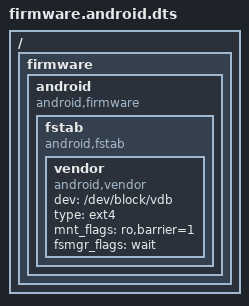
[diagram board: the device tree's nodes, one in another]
/ {
    firmware {
        android {
            compatible = "android,firmware";
            fstab {
                compatible = "android,fstab";
                vendor {
                    compatible = "android,vendor";
                    dev = "/dev/block/vdb";
                    type = "ext4";
                    mnt_flags = "ro,barrier=1";
                    fsmgr_flags = "wait";
                };
            };
        };
    };
};
